VERSION "Hyundai Custin 1st gen front radar, reverse engineered from own-car rlog 2026-08"

NS_ :

BS_:

BU_: XXX RADAR

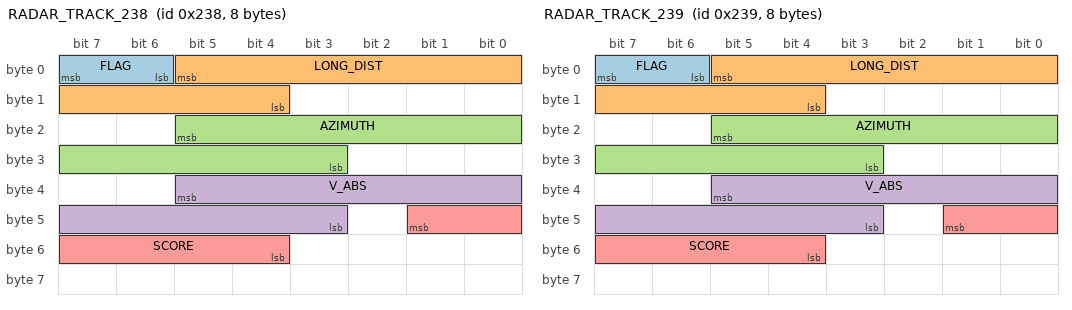
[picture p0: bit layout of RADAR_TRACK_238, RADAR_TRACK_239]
BO_ 568 RADAR_TRACK_238: 8 RADAR
 SG_ FLAG : 7|2@0+ (1,0) [0|3] "" XXX
 SG_ LONG_DIST : 5|10@0+ (0.1,0) [0|102.3] "m" XXX
 SG_ AZIMUTH : 21|11@0- (0.0388,0) [-39.7312|39.6924] "deg" XXX
 SG_ V_ABS : 37|11@0- (0.02526,2.587) [-23.2792|28.428] "m/s" XXX
 SG_ SCORE : 41|6@0+ (1,0) [0|63] "" XXX

BO_ 569 RADAR_TRACK_239: 8 RADAR
 SG_ FLAG : 7|2@0+ (1,0) [0|3] "" XXX
 SG_ LONG_DIST : 5|10@0+ (0.1,0) [0|102.3] "m" XXX
 SG_ AZIMUTH : 21|11@0- (0.0388,0) [-39.7312|39.6924] "deg" XXX
 SG_ V_ABS : 37|11@0- (0.02526,2.587) [-23.2792|28.428] "m/s" XXX
 SG_ SCORE : 41|6@0+ (1,0) [0|63] "" XXX

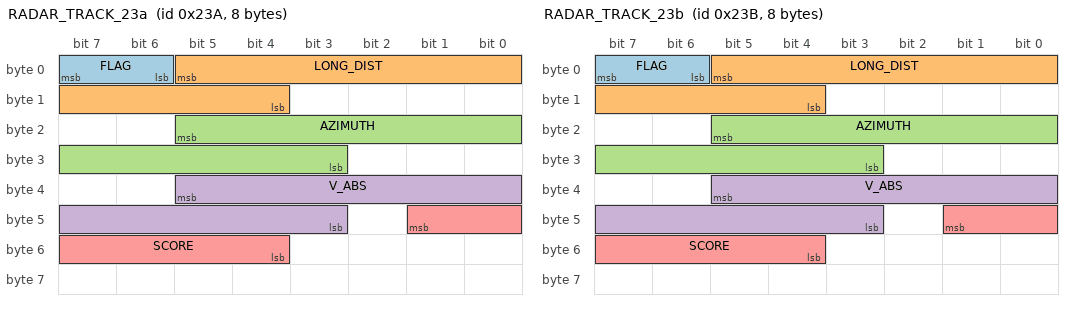
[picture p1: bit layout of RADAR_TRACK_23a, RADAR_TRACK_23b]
BO_ 570 RADAR_TRACK_23a: 8 RADAR
 SG_ FLAG : 7|2@0+ (1,0) [0|3] "" XXX
 SG_ LONG_DIST : 5|10@0+ (0.1,0) [0|102.3] "m" XXX
 SG_ AZIMUTH : 21|11@0- (0.0388,0) [-39.7312|39.6924] "deg" XXX
 SG_ V_ABS : 37|11@0- (0.02526,2.587) [-23.2792|28.428] "m/s" XXX
 SG_ SCORE : 41|6@0+ (1,0) [0|63] "" XXX

BO_ 571 RADAR_TRACK_23b: 8 RADAR
 SG_ FLAG : 7|2@0+ (1,0) [0|3] "" XXX
 SG_ LONG_DIST : 5|10@0+ (0.1,0) [0|102.3] "m" XXX
 SG_ AZIMUTH : 21|11@0- (0.0388,0) [-39.7312|39.6924] "deg" XXX
 SG_ V_ABS : 37|11@0- (0.02526,2.587) [-23.2792|28.428] "m/s" XXX
 SG_ SCORE : 41|6@0+ (1,0) [0|63] "" XXX

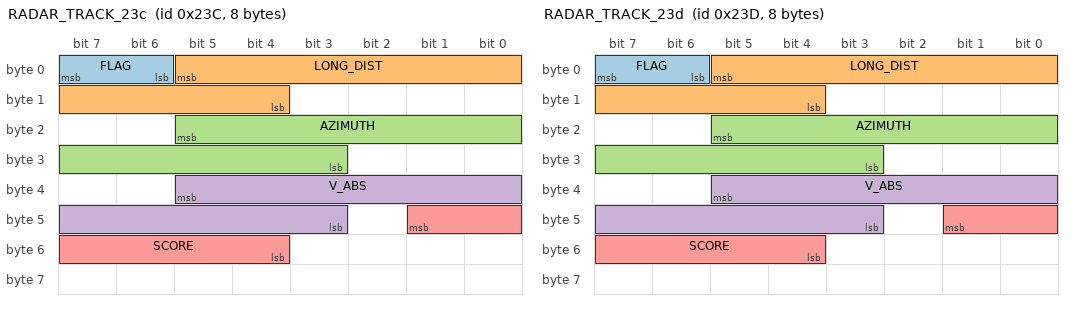
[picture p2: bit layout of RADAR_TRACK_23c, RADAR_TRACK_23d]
BO_ 572 RADAR_TRACK_23c: 8 RADAR
 SG_ FLAG : 7|2@0+ (1,0) [0|3] "" XXX
 SG_ LONG_DIST : 5|10@0+ (0.1,0) [0|102.3] "m" XXX
 SG_ AZIMUTH : 21|11@0- (0.0388,0) [-39.7312|39.6924] "deg" XXX
 SG_ V_ABS : 37|11@0- (0.02526,2.587) [-23.2792|28.428] "m/s" XXX
 SG_ SCORE : 41|6@0+ (1,0) [0|63] "" XXX

BO_ 573 RADAR_TRACK_23d: 8 RADAR
 SG_ FLAG : 7|2@0+ (1,0) [0|3] "" XXX
 SG_ LONG_DIST : 5|10@0+ (0.1,0) [0|102.3] "m" XXX
 SG_ AZIMUTH : 21|11@0- (0.0388,0) [-39.7312|39.6924] "deg" XXX
 SG_ V_ABS : 37|11@0- (0.02526,2.587) [-23.2792|28.428] "m/s" XXX
 SG_ SCORE : 41|6@0+ (1,0) [0|63] "" XXX

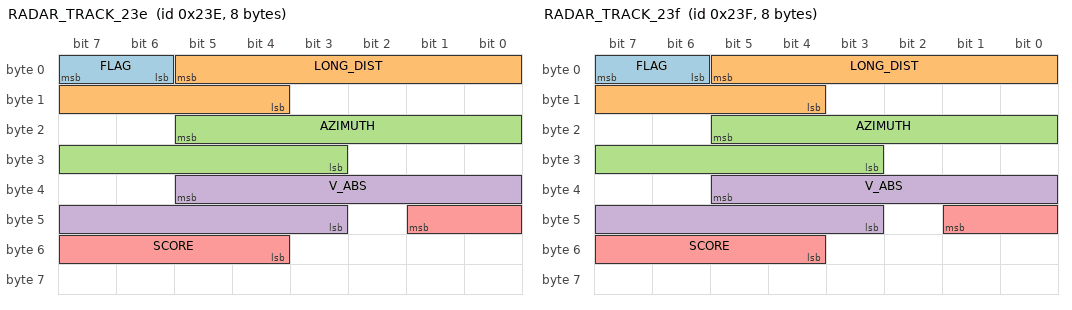
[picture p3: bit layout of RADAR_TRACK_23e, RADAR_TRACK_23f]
BO_ 574 RADAR_TRACK_23e: 8 RADAR
 SG_ FLAG : 7|2@0+ (1,0) [0|3] "" XXX
 SG_ LONG_DIST : 5|10@0+ (0.1,0) [0|102.3] "m" XXX
 SG_ AZIMUTH : 21|11@0- (0.0388,0) [-39.7312|39.6924] "deg" XXX
 SG_ V_ABS : 37|11@0- (0.02526,2.587) [-23.2792|28.428] "m/s" XXX
 SG_ SCORE : 41|6@0+ (1,0) [0|63] "" XXX

BO_ 575 RADAR_TRACK_23f: 8 RADAR
 SG_ FLAG : 7|2@0+ (1,0) [0|3] "" XXX
 SG_ LONG_DIST : 5|10@0+ (0.1,0) [0|102.3] "m" XXX
 SG_ AZIMUTH : 21|11@0- (0.0388,0) [-39.7312|39.6924] "deg" XXX
 SG_ V_ABS : 37|11@0- (0.02526,2.587) [-23.2792|28.428] "m/s" XXX
 SG_ SCORE : 41|6@0+ (1,0) [0|63] "" XXX

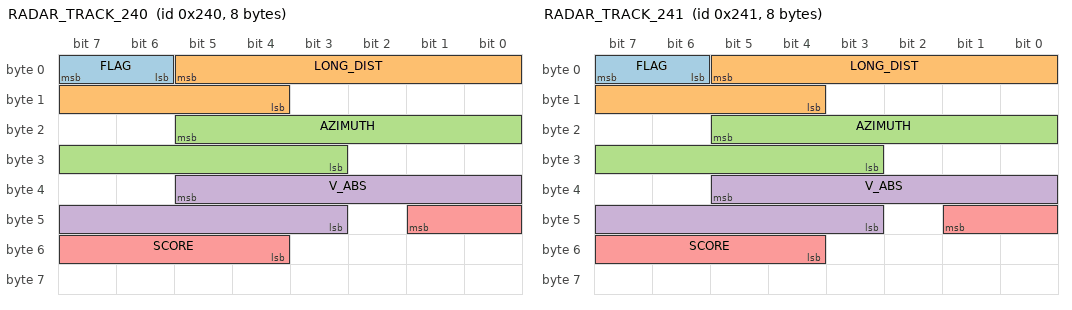
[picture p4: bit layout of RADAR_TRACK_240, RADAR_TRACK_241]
BO_ 576 RADAR_TRACK_240: 8 RADAR
 SG_ FLAG : 7|2@0+ (1,0) [0|3] "" XXX
 SG_ LONG_DIST : 5|10@0+ (0.1,0) [0|102.3] "m" XXX
 SG_ AZIMUTH : 21|11@0- (0.0388,0) [-39.7312|39.6924] "deg" XXX
 SG_ V_ABS : 37|11@0- (0.02526,2.587) [-23.2792|28.428] "m/s" XXX
 SG_ SCORE : 41|6@0+ (1,0) [0|63] "" XXX

BO_ 577 RADAR_TRACK_241: 8 RADAR
 SG_ FLAG : 7|2@0+ (1,0) [0|3] "" XXX
 SG_ LONG_DIST : 5|10@0+ (0.1,0) [0|102.3] "m" XXX
 SG_ AZIMUTH : 21|11@0- (0.0388,0) [-39.7312|39.6924] "deg" XXX
 SG_ V_ABS : 37|11@0- (0.02526,2.587) [-23.2792|28.428] "m/s" XXX
 SG_ SCORE : 41|6@0+ (1,0) [0|63] "" XXX

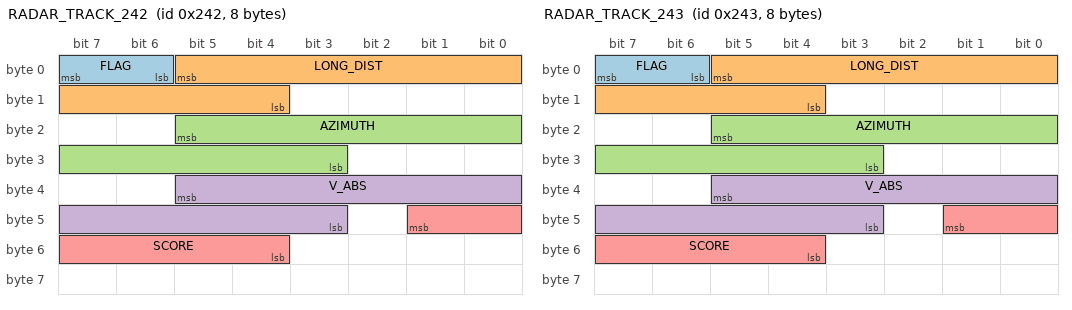
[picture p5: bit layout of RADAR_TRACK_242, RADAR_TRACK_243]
BO_ 578 RADAR_TRACK_242: 8 RADAR
 SG_ FLAG : 7|2@0+ (1,0) [0|3] "" XXX
 SG_ LONG_DIST : 5|10@0+ (0.1,0) [0|102.3] "m" XXX
 SG_ AZIMUTH : 21|11@0- (0.0388,0) [-39.7312|39.6924] "deg" XXX
 SG_ V_ABS : 37|11@0- (0.02526,2.587) [-23.2792|28.428] "m/s" XXX
 SG_ SCORE : 41|6@0+ (1,0) [0|63] "" XXX

BO_ 579 RADAR_TRACK_243: 8 RADAR
 SG_ FLAG : 7|2@0+ (1,0) [0|3] "" XXX
 SG_ LONG_DIST : 5|10@0+ (0.1,0) [0|102.3] "m" XXX
 SG_ AZIMUTH : 21|11@0- (0.0388,0) [-39.7312|39.6924] "deg" XXX
 SG_ V_ABS : 37|11@0- (0.02526,2.587) [-23.2792|28.428] "m/s" XXX
 SG_ SCORE : 41|6@0+ (1,0) [0|63] "" XXX

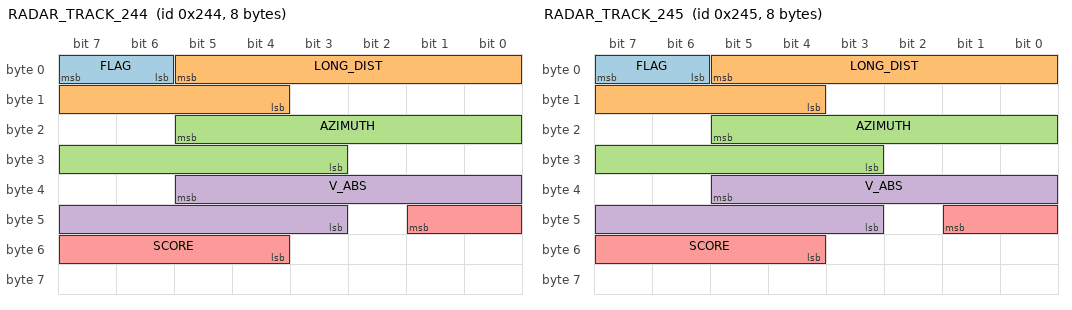
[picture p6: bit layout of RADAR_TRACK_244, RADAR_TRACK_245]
BO_ 580 RADAR_TRACK_244: 8 RADAR
 SG_ FLAG : 7|2@0+ (1,0) [0|3] "" XXX
 SG_ LONG_DIST : 5|10@0+ (0.1,0) [0|102.3] "m" XXX
 SG_ AZIMUTH : 21|11@0- (0.0388,0) [-39.7312|39.6924] "deg" XXX
 SG_ V_ABS : 37|11@0- (0.02526,2.587) [-23.2792|28.428] "m/s" XXX
 SG_ SCORE : 41|6@0+ (1,0) [0|63] "" XXX

BO_ 581 RADAR_TRACK_245: 8 RADAR
 SG_ FLAG : 7|2@0+ (1,0) [0|3] "" XXX
 SG_ LONG_DIST : 5|10@0+ (0.1,0) [0|102.3] "m" XXX
 SG_ AZIMUTH : 21|11@0- (0.0388,0) [-39.7312|39.6924] "deg" XXX
 SG_ V_ABS : 37|11@0- (0.02526,2.587) [-23.2792|28.428] "m/s" XXX
 SG_ SCORE : 41|6@0+ (1,0) [0|63] "" XXX

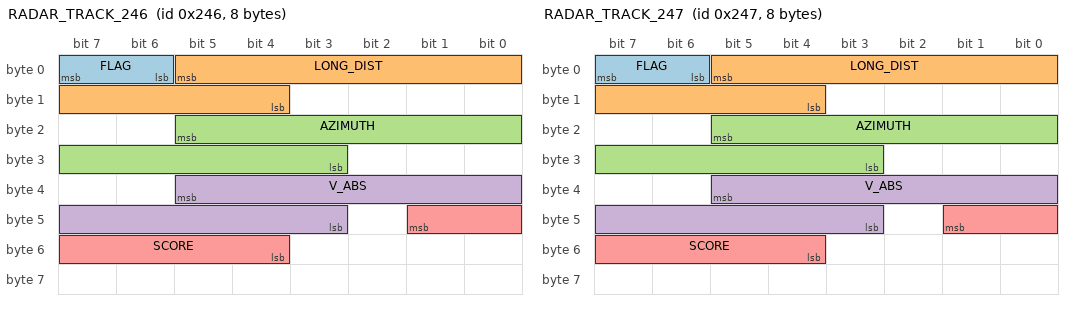
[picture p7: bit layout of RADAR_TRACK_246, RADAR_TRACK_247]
BO_ 582 RADAR_TRACK_246: 8 RADAR
 SG_ FLAG : 7|2@0+ (1,0) [0|3] "" XXX
 SG_ LONG_DIST : 5|10@0+ (0.1,0) [0|102.3] "m" XXX
 SG_ AZIMUTH : 21|11@0- (0.0388,0) [-39.7312|39.6924] "deg" XXX
 SG_ V_ABS : 37|11@0- (0.02526,2.587) [-23.2792|28.428] "m/s" XXX
 SG_ SCORE : 41|6@0+ (1,0) [0|63] "" XXX

BO_ 583 RADAR_TRACK_247: 8 RADAR
 SG_ FLAG : 7|2@0+ (1,0) [0|3] "" XXX
 SG_ LONG_DIST : 5|10@0+ (0.1,0) [0|102.3] "m" XXX
 SG_ AZIMUTH : 21|11@0- (0.0388,0) [-39.7312|39.6924] "deg" XXX
 SG_ V_ABS : 37|11@0- (0.02526,2.587) [-23.2792|28.428] "m/s" XXX
 SG_ SCORE : 41|6@0+ (1,0) [0|63] "" XXX

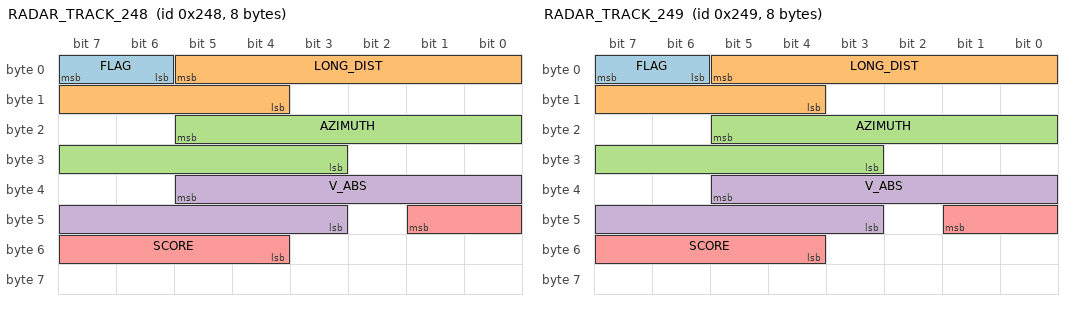
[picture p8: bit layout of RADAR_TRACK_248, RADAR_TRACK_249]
BO_ 584 RADAR_TRACK_248: 8 RADAR
 SG_ FLAG : 7|2@0+ (1,0) [0|3] "" XXX
 SG_ LONG_DIST : 5|10@0+ (0.1,0) [0|102.3] "m" XXX
 SG_ AZIMUTH : 21|11@0- (0.0388,0) [-39.7312|39.6924] "deg" XXX
 SG_ V_ABS : 37|11@0- (0.02526,2.587) [-23.2792|28.428] "m/s" XXX
 SG_ SCORE : 41|6@0+ (1,0) [0|63] "" XXX

BO_ 585 RADAR_TRACK_249: 8 RADAR
 SG_ FLAG : 7|2@0+ (1,0) [0|3] "" XXX
 SG_ LONG_DIST : 5|10@0+ (0.1,0) [0|102.3] "m" XXX
 SG_ AZIMUTH : 21|11@0- (0.0388,0) [-39.7312|39.6924] "deg" XXX
 SG_ V_ABS : 37|11@0- (0.02526,2.587) [-23.2792|28.428] "m/s" XXX
 SG_ SCORE : 41|6@0+ (1,0) [0|63] "" XXX

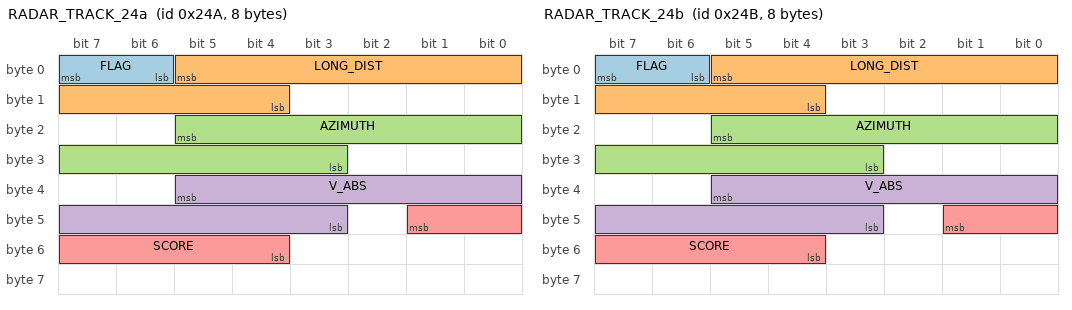
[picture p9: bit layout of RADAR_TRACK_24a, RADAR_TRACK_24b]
BO_ 586 RADAR_TRACK_24a: 8 RADAR
 SG_ FLAG : 7|2@0+ (1,0) [0|3] "" XXX
 SG_ LONG_DIST : 5|10@0+ (0.1,0) [0|102.3] "m" XXX
 SG_ AZIMUTH : 21|11@0- (0.0388,0) [-39.7312|39.6924] "deg" XXX
 SG_ V_ABS : 37|11@0- (0.02526,2.587) [-23.2792|28.428] "m/s" XXX
 SG_ SCORE : 41|6@0+ (1,0) [0|63] "" XXX

BO_ 587 RADAR_TRACK_24b: 8 RADAR
 SG_ FLAG : 7|2@0+ (1,0) [0|3] "" XXX
 SG_ LONG_DIST : 5|10@0+ (0.1,0) [0|102.3] "m" XXX
 SG_ AZIMUTH : 21|11@0- (0.0388,0) [-39.7312|39.6924] "deg" XXX
 SG_ V_ABS : 37|11@0- (0.02526,2.587) [-23.2792|28.428] "m/s" XXX
 SG_ SCORE : 41|6@0+ (1,0) [0|63] "" XXX

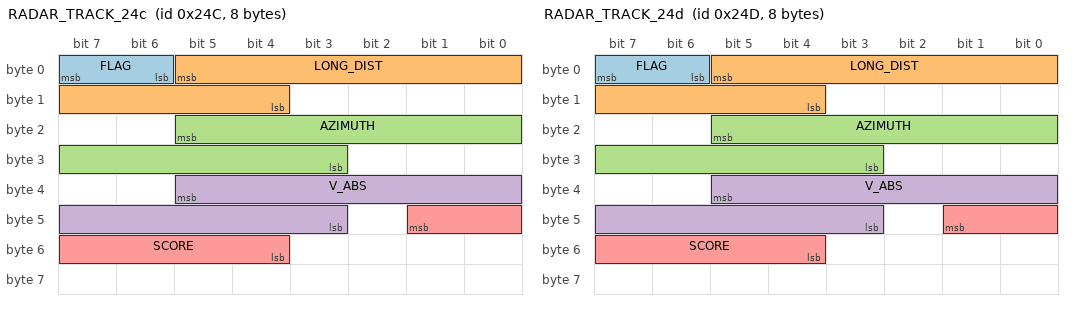
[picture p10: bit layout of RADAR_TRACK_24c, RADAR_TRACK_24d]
BO_ 588 RADAR_TRACK_24c: 8 RADAR
 SG_ FLAG : 7|2@0+ (1,0) [0|3] "" XXX
 SG_ LONG_DIST : 5|10@0+ (0.1,0) [0|102.3] "m" XXX
 SG_ AZIMUTH : 21|11@0- (0.0388,0) [-39.7312|39.6924] "deg" XXX
 SG_ V_ABS : 37|11@0- (0.02526,2.587) [-23.2792|28.428] "m/s" XXX
 SG_ SCORE : 41|6@0+ (1,0) [0|63] "" XXX

BO_ 589 RADAR_TRACK_24d: 8 RADAR
 SG_ FLAG : 7|2@0+ (1,0) [0|3] "" XXX
 SG_ LONG_DIST : 5|10@0+ (0.1,0) [0|102.3] "m" XXX
 SG_ AZIMUTH : 21|11@0- (0.0388,0) [-39.7312|39.6924] "deg" XXX
 SG_ V_ABS : 37|11@0- (0.02526,2.587) [-23.2792|28.428] "m/s" XXX
 SG_ SCORE : 41|6@0+ (1,0) [0|63] "" XXX

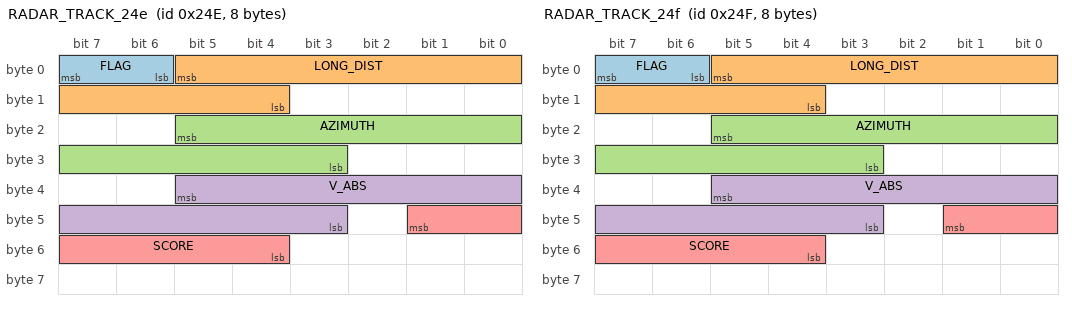
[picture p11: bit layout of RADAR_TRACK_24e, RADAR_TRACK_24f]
BO_ 590 RADAR_TRACK_24e: 8 RADAR
 SG_ FLAG : 7|2@0+ (1,0) [0|3] "" XXX
 SG_ LONG_DIST : 5|10@0+ (0.1,0) [0|102.3] "m" XXX
 SG_ AZIMUTH : 21|11@0- (0.0388,0) [-39.7312|39.6924] "deg" XXX
 SG_ V_ABS : 37|11@0- (0.02526,2.587) [-23.2792|28.428] "m/s" XXX
 SG_ SCORE : 41|6@0+ (1,0) [0|63] "" XXX

BO_ 591 RADAR_TRACK_24f: 8 RADAR
 SG_ FLAG : 7|2@0+ (1,0) [0|3] "" XXX
 SG_ LONG_DIST : 5|10@0+ (0.1,0) [0|102.3] "m" XXX
 SG_ AZIMUTH : 21|11@0- (0.0388,0) [-39.7312|39.6924] "deg" XXX
 SG_ V_ABS : 37|11@0- (0.02526,2.587) [-23.2792|28.428] "m/s" XXX
 SG_ SCORE : 41|6@0+ (1,0) [0|63] "" XXX

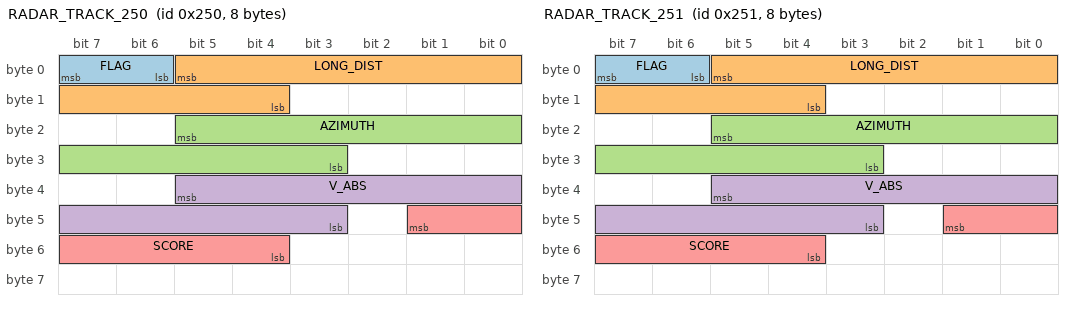
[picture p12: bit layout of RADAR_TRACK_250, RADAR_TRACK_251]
BO_ 592 RADAR_TRACK_250: 8 RADAR
 SG_ FLAG : 7|2@0+ (1,0) [0|3] "" XXX
 SG_ LONG_DIST : 5|10@0+ (0.1,0) [0|102.3] "m" XXX
 SG_ AZIMUTH : 21|11@0- (0.0388,0) [-39.7312|39.6924] "deg" XXX
 SG_ V_ABS : 37|11@0- (0.02526,2.587) [-23.2792|28.428] "m/s" XXX
 SG_ SCORE : 41|6@0+ (1,0) [0|63] "" XXX

BO_ 593 RADAR_TRACK_251: 8 RADAR
 SG_ FLAG : 7|2@0+ (1,0) [0|3] "" XXX
 SG_ LONG_DIST : 5|10@0+ (0.1,0) [0|102.3] "m" XXX
 SG_ AZIMUTH : 21|11@0- (0.0388,0) [-39.7312|39.6924] "deg" XXX
 SG_ V_ABS : 37|11@0- (0.02526,2.587) [-23.2792|28.428] "m/s" XXX
 SG_ SCORE : 41|6@0+ (1,0) [0|63] "" XXX

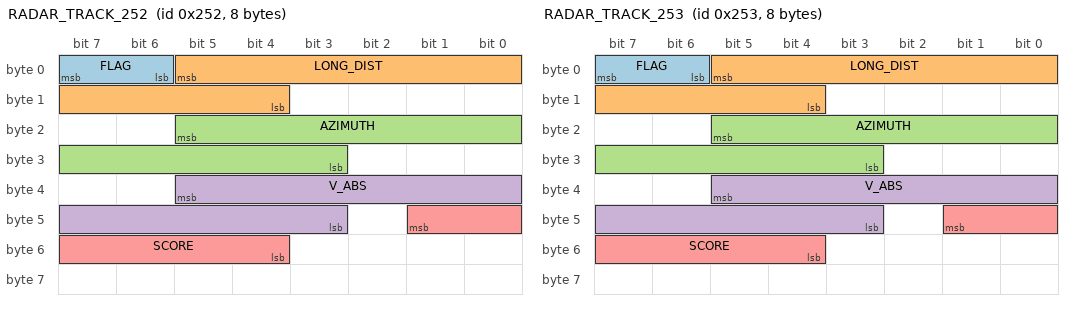
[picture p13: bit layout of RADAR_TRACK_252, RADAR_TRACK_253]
BO_ 594 RADAR_TRACK_252: 8 RADAR
 SG_ FLAG : 7|2@0+ (1,0) [0|3] "" XXX
 SG_ LONG_DIST : 5|10@0+ (0.1,0) [0|102.3] "m" XXX
 SG_ AZIMUTH : 21|11@0- (0.0388,0) [-39.7312|39.6924] "deg" XXX
 SG_ V_ABS : 37|11@0- (0.02526,2.587) [-23.2792|28.428] "m/s" XXX
 SG_ SCORE : 41|6@0+ (1,0) [0|63] "" XXX

BO_ 595 RADAR_TRACK_253: 8 RADAR
 SG_ FLAG : 7|2@0+ (1,0) [0|3] "" XXX
 SG_ LONG_DIST : 5|10@0+ (0.1,0) [0|102.3] "m" XXX
 SG_ AZIMUTH : 21|11@0- (0.0388,0) [-39.7312|39.6924] "deg" XXX
 SG_ V_ABS : 37|11@0- (0.02526,2.587) [-23.2792|28.428] "m/s" XXX
 SG_ SCORE : 41|6@0+ (1,0) [0|63] "" XXX

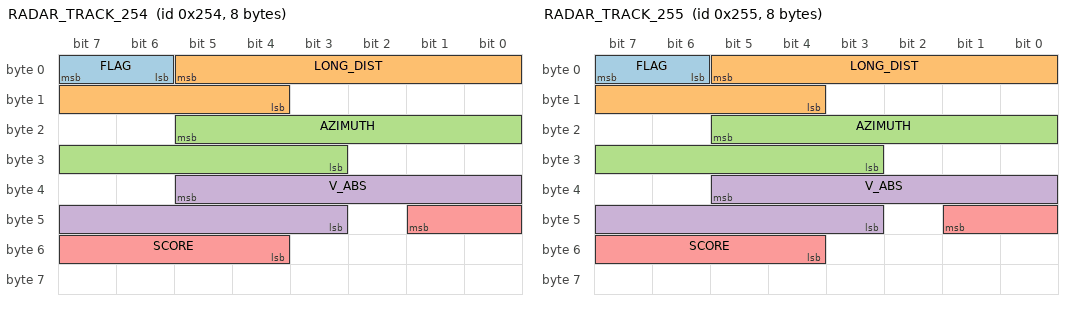
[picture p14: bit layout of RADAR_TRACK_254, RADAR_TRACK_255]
BO_ 596 RADAR_TRACK_254: 8 RADAR
 SG_ FLAG : 7|2@0+ (1,0) [0|3] "" XXX
 SG_ LONG_DIST : 5|10@0+ (0.1,0) [0|102.3] "m" XXX
 SG_ AZIMUTH : 21|11@0- (0.0388,0) [-39.7312|39.6924] "deg" XXX
 SG_ V_ABS : 37|11@0- (0.02526,2.587) [-23.2792|28.428] "m/s" XXX
 SG_ SCORE : 41|6@0+ (1,0) [0|63] "" XXX

BO_ 597 RADAR_TRACK_255: 8 RADAR
 SG_ FLAG : 7|2@0+ (1,0) [0|3] "" XXX
 SG_ LONG_DIST : 5|10@0+ (0.1,0) [0|102.3] "m" XXX
 SG_ AZIMUTH : 21|11@0- (0.0388,0) [-39.7312|39.6924] "deg" XXX
 SG_ V_ABS : 37|11@0- (0.02526,2.587) [-23.2792|28.428] "m/s" XXX
 SG_ SCORE : 41|6@0+ (1,0) [0|63] "" XXX

CM_ BO_ 568 "0x238 is the ACC-selected primary target; 0x239-0x255 are the raw track list.";
CM_ SG_ 568 LONG_DIST "Slant range. Validity is range > 0.5, STATE is not reliable.";
CM_ SG_ 568 AZIMUTH "Polar angle. dRel = cos(az)*range, yRel = -sin(az)*range.";
CM_ SG_ 568 V_ABS "Target absolute speed, NOT relative. vRel = V_ABS - vEgo.";
